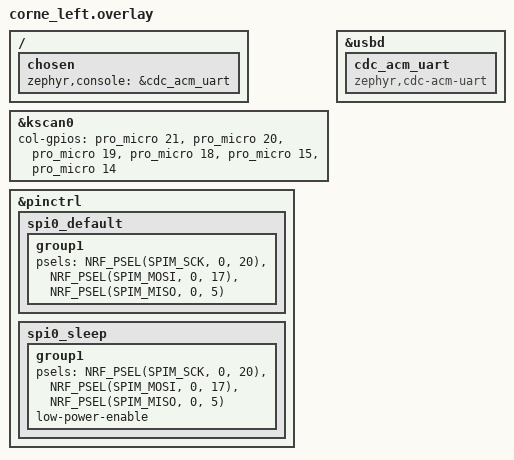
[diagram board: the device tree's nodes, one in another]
/*
 * Copyright (c) 2020 Pete Johanson
 *
 * SPDX-License-Identifier: MIT
 */

#include "corne.dtsi"

&kscan0 {
	col-gpios
	= <&pro_micro 21 GPIO_ACTIVE_HIGH>
	, <&pro_micro 20 GPIO_ACTIVE_HIGH>
	, <&pro_micro 19 GPIO_ACTIVE_HIGH>
	, <&pro_micro 18 GPIO_ACTIVE_HIGH>
	, <&pro_micro 15 GPIO_ACTIVE_HIGH>
	, <&pro_micro 14 GPIO_ACTIVE_HIGH>
	;
};

&pinctrl {
	spi0_default: spi0_default {
		group1 {
			psels = <NRF_PSEL(SPIM_SCK, 0, 20)>,
					<NRF_PSEL(SPIM_MOSI, 0, 17)>,
					<NRF_PSEL(SPIM_MISO, 0, 5)>;
		};
	};

	spi0_sleep: spi0_sleep {
		group1 {
			psels = <NRF_PSEL(SPIM_SCK, 0, 20)>,
					<NRF_PSEL(SPIM_MOSI, 0, 17)>,
					<NRF_PSEL(SPIM_MISO, 0, 5)>;
			low-power-enable;
		};
	};
};

&usbd {
	status = "okay";

	cdc_acm_uart: cdc_acm_uart {
		compatible = "zephyr,cdc-acm-uart";
	};
};

/ {
	chosen {
		zephyr,console = &cdc_acm_uart;
	};
};
